# R7FA8D1BH register map
Vendor: Renesas; Series: RA8; File version: 1.2
CPU: CM85 r0p0, little endian, MPU, FPU, VTOR, 4 interrupt priority bits
Registers are 32-bit, read-write, reset 0x0 unless marked. A register's access mark holds for its fields unless they carry their own. Offsets are from the block's base; [hi:lo] are bit positions; <NAME> marks a mode.

## CRC — CRC Calculator
Base 0x40310000
Same registers: CRC_NS 0x50310000
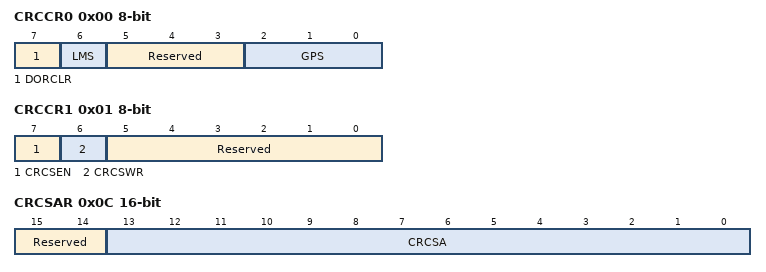
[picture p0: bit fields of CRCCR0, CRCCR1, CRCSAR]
0x00 CRCCR0 8-bit — CRC Control Register0
  [7] DORCLR wo — CRCDOR Register Clear
    0=No effect; 1=Clears the CRCDOR register
  [6] LMS — CRC Calculation Switching
    0=Generates CRC for LSB first communication; 1=Generates CRC for MSB first communication
  [5:3] Reserved — These bits are read as 000. The write value should be 000.
  [2:0] GPS — CRC Generating Polynomial Switching
    0=No calculation is executed; 1=8-bit CRC-8 (X8 + X2 + X + 1); 2=16-bit CRC-16 (X16 + X15 + X2 + 1); 3=16-bit CRC-CCITT (X16 + X12 + X5 + 1); 4=32-bit CRC-32 (X32+X26+X23+X22+X16+X12+X11+X10+X8+X7+X5+X4+X2+X+1); 5=32-bit CRC-32C (X32+X28+X27+X26+ X25+X23+X22+X20+X19+X18+X14+X13+X11+X10+X9+X8+X6+1); other=others (No calculation is executed.)
0x01 CRCCR1 8-bit — CRC Control Register1
  [7] CRCSEN — Snoop enable bit
    0=Disabled; 1=Enabled
  [6] CRCSWR — Snoop-on-write/read switch bit
    0=Snoop-on-read; 1=Snoop-on-write
  [5:0] Reserved — These bits are read as 000000. The write value should be 000000.
0x04 CRCDIR — CRC Data Input Register
  [31:0] CRCDIR — Calculation input Data (Case of CRC-32, CRC-32C )
0x04 CRCDIR_BY 8-bit (alternate view of CRCDIR) — CRC Data Input Register (byte access)
  [7:0] CRCDIR_BY — Calculation input Data ( Case of CRC-8, CRC-16 or CRC-CCITT )
0x08 CRCDOR — CRC Data Output Register
  [31:0] CRCDOR — Calculation output Data (Case of CRC-32, CRC-32C )
0x08 CRCDOR_HA 16-bit (alternate view of CRCDOR) — CRC Data Output Register (halfword access)
  [15:0] CRCDOR_HA — Calculation output Data (Case of CRC-16 or CRC-CCITT )
0x08 CRCDOR_BY 8-bit (alternate view of CRCDOR) — CRC Data Output Register(byte access)
  [7:0] CRCDOR_BY — Calculation output Data (Case of CRC-8 )
0x0C CRCSAR 16-bit — Snoop Address Register
  [15:14] Reserved — These bits are read as 00. The write value should be 00.
  [13:0] CRCSA — snoop address bitSet the I/O register address to snoop
    3=SCI0.TDR; 5=SCI0.RDR; 35=SCI1.TDR; 37=SCI1.RDR; 67=SCI2.TDR; 69=SCI2.RDR; 99=SCI3.TDR; 101=SCI3.RDR; 131=SCI4.TDR; 133=SCI4.RDR; 163=SCI5.TDR; 165=SCI5.RDR; 195=SCI6.TDR; 197=SCI6.RDR; 227=SCI7.TDR; 229=SCI7.RDR; 0x103=SCI8.TDR; 0x105=SCI8.RDR; 0x123=SCI9.TDR; 0x125=SCI9.RDR; other=others (Settings other than above are prohibited.)

## DOC — Data Operation Circuit-4
Base 0x40311000
Same registers: DOC_NS 0x50311000
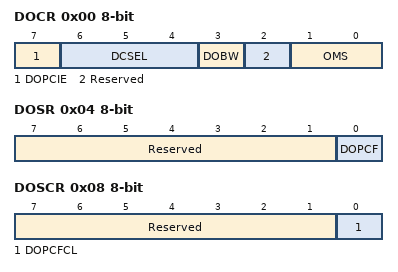
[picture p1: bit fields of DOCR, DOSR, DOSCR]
0x00 DOCR 8-bit — DOC Control Register
  [7] DOPCIE — Data Operation Circuit Interrput Enable
    0=Disables interrupts from the data operation circuit; 1=Enables interrupts from the data operation circuit
  [6:4] DCSEL — Detection Condition Select
    0=Data mismatch( DODSR0 ≠ DODIR ); 1=Data match( DODSR0 = DODIR ); 2=Data lower( DODSR0 > DODIR ); 3=Data upper( DODSR0 < DODIR ); 4=Data inside window( DODSR0 < DODIR < DODSR1 ); 5=Data outside window( DODIR < DODSR0, DODSR1 <DODIR ); 6=Setting prohibited; 7=Setting prohibited
  [3] DOBW — Data Operation Width Select
    0=16-bit; 1=32-bit
  [2] Reserved — This bit is read as 0. The write value should be 0.
  [1:0] OMS — Operating Mode Select
    0=Data comparison mode; 1=Data addition mode; 2=Data subtraction mode; 3=Setting prohibited
0x04 DOSR 8-bit ro read-modifies — Data Operation Circuit Flag Status Register
  [7:1] Reserved — These bits are read as 0000000.
  [0] DOPCF read-modifies — Data Operation Circuit Flag
0x08 DOSCR 8-bit wo — Data Operation Circuit Flag Status Clear Register
  [7:1] Reserved — The write value should be 0000000.
  [0] DOPCFCL — Data Operation Circuit Flag Clear
    0=Maintains the DOPCF flag state; 1=Clears the DOPCF flag
0x0C DODIR — Data Operation Circuit Data Input Register
  [31:0] DODIR read-modifies — DODIR is a readable/writable register which can store the data in the operations.
0x0C DODIR_HA 16-bit — Data Operation Circuit Data Input Register
  [15:0] DODIR_HA — DODIR_HA is a readable/writable register which can store the data in the operations.
0x10 DODSR0 read-modifies — Data Operation Circuit Data Setting Register0
  [31:0] DODSR0 read-modifies — DODSR0 is a readable/writable register which can store a reference data in the data comparison mode and the result of data addition/subtraction mode.
0x10 DODSR0_HA 16-bit read-modifies — Data Operation Circuit Data Setting Register0
  [15:0] DODSR0_HA read-modifies — DODSR0_HA is a readable/writable register which can store a reference data in the data comparison mode and the result of data addition/subtraction mode.
0x14 DODSR1 — Data Operation Circuit Data Setting Register1
  [31:0] DODSR1 read-modifies — DODSR1 is a readable/writable register which can store a reference data in the data window comparison mode
0x14 DODSR1_HA 16-bit — Data Operation Circuit Data Setting Register1
  [15:0] DODSR1_HA — DODSR1_HA is a readable/writable register which can store a reference data in the data window comparison mode
